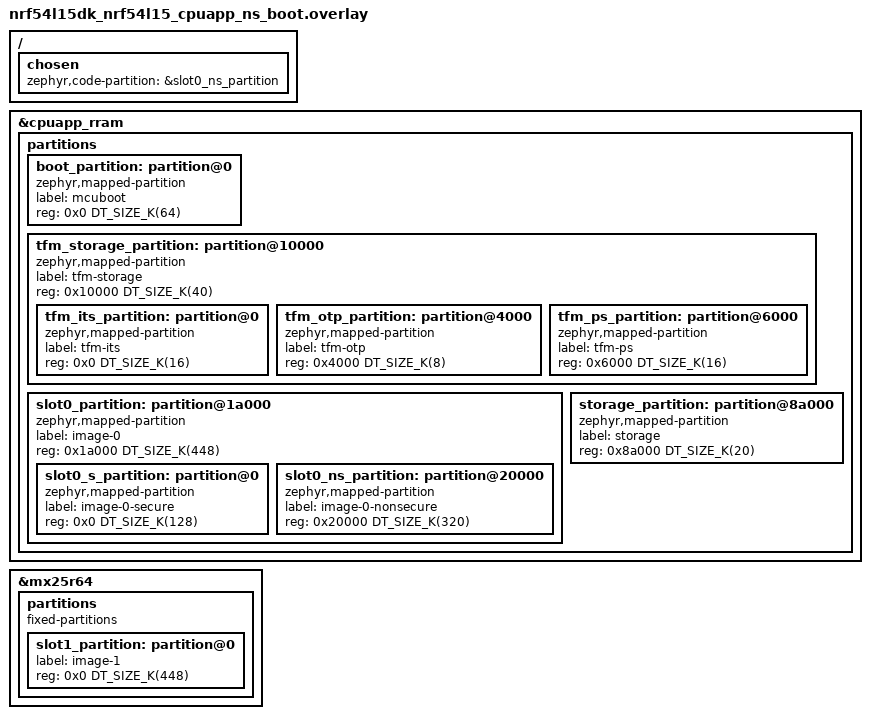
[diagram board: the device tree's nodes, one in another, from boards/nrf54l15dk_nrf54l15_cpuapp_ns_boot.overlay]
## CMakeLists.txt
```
#
# Copyright (c) 2022-2026 Nordic Semiconductor
#
# SPDX-License-Identifier: LicenseRef-Nordic-5-Clause
#
cmake_minimum_required(VERSION 3.20.0)

find_package(Zephyr REQUIRED HINTS $ENV{ZEPHYR_BASE})
project(input_device)

if(CONFIG_PROVISIONER)
  add_subdirectory(provisioner)
else()
  add_subdirectory(src)
  target_include_directories(app PRIVATE include)
endif()
```

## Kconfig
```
#
# Copyright (c) 2024-2026 Nordic Semiconductor
#
# SPDX-License-Identifier: LicenseRef-Nordic-5-Clause
#

source "Kconfig.zephyr"

config SETTINGS
	default y

config ZMS
	default y if (SOC_FLASH_NRF_RRAM || SOC_FLASH_NRF_MRAM)

config NVS
	default y if !(SOC_FLASH_NRF_RRAM || SOC_FLASH_NRF_MRAM)
```

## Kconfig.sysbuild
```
#
# Copyright (c) 2023-2026 Nordic Semiconductor
#
# SPDX-License-Identifier: LicenseRef-Nordic-5-Clause
#

config PARTITION_MANAGER
	default n

menu "Fast Pair credentials"

config BT_FAST_PAIR_MODEL_ID
	default 0x2A410B

# The Anti-Spoofing Private Key is confidential and must be handled securely.
# The following key is only used for demonstration purposes and must not be used in production.
config BT_FAST_PAIR_ANTI_SPOOFING_PRIVATE_KEY
	default "Unoh+nycK/ZJ7k3dHsdcNpiP1SfOy0P/Lx5XixyYois="

endmenu

config NRF_DEFAULT_IPC_RADIO
	default y

source "share/sysbuild/Kconfig"
```

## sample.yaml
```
sample:
  name: Fast Pair input device
  description: Bluetooth Fast Pair Provider sample setup for the input device use
    case
tests:
  sample.bluetooth.fast_pair.input_device:
    build_only: true
    sysbuild: true
    integration_platforms:
      - nrf52dk/nrf52832
      - nrf52840dk/nrf52840
      - nrf5340dk/nrf5340/cpuapp
      - nrf54l15dk/nrf54l05/cpuapp
      - nrf54l15dk/nrf54l15/cpuapp/ns
      - nrf54lm20dk/nrf54lm20a/cpuapp
      - nrf54lm20dk/nrf54lm20b/cpuapp
      - nrf54ls05dk/nrf54ls05b/cpuapp
    platform_allow:
      - nrf52dk/nrf52832
      - nrf52840dk/nrf52840
      - nrf5340dk/nrf5340/cpuapp
      - nrf54l15dk/nrf54l05/cpuapp
      - nrf54l15dk/nrf54l10/cpuapp
      - nrf54l15dk/nrf54l15/cpuapp
      - nrf54l15dk/nrf54l15/cpuapp/ns
      - nrf54lm20dk/nrf54lm20a/cpuapp
      - nrf54lm20dk/nrf54lm20b/cpuapp
      - nrf54ls05dk/nrf54ls05b/cpuapp
    tags:
      - bluetooth
      - ci_build
      - sysbuild
      - ci_samples_bluetooth
  sample.bluetooth.fast_pair.input_device.pm_legacy:
    build_only: true
    sysbuild: true
    integration_platforms:
      - nrf52840dk/nrf52840
      - nrf5340dk/nrf5340/cpuapp
      - nrf5340dk/nrf5340/cpuapp/ns
      - nrf54l15dk/nrf54l15/cpuapp
    platform_allow:
      - nrf52840dk/nrf52840
      - nrf5340dk/nrf5340/cpuapp
      - nrf5340dk/nrf5340/cpuapp/ns
      - nrf54l15dk/nrf54l15/cpuapp
    tags:
      - bluetooth
      - ci_build
      - sysbuild
      - ci_samples_bluetooth
    extra_args:
      - SB_CONFIG_PARTITION_MANAGER=y

  sample.bluetooth.fast_pair.input_device.ns.provisioner:
    build_only: true
    sysbuild: true
    integration_platforms:
      - nrf54l15dk/nrf54l15/cpuapp/ns
    platform_allow:
      - nrf54l15dk/nrf54l15/cpuapp/ns
    tags:
      - bluetooth
      - ci_build
      - sysbuild
      - ci_samples_bluetooth
    extra_args:
      - FILE_SUFFIX=provisioner

  sample.bluetooth.fast_pair.input_device.ns.mcuboot:
    build_only: true
    sysbuild: true
    integration_platforms:
      - nrf54l15dk/nrf54l15/cpuapp/ns
    platform_allow:
      - nrf54l15dk/nrf54l15/cpuapp/ns
    tags:
      - bluetooth
      - ci_build
      - sysbuild
      - ci_samples_bluetooth
    extra_args:
      - FILE_SUFFIX=mcuboot

  sample.bluetooth.fast_pair.input_device.ns.mcuboot_provisioner:
    build_only: true
    sysbuild: true
    integration_platforms:
      - nrf54l15dk/nrf54l15/cpuapp/ns
    platform_allow:
      - nrf54l15dk/nrf54l15/cpuapp/ns
    tags:
      - bluetooth
      - ci_build
      - sysbuild
      - ci_samples_bluetooth
    extra_args:
      - FILE_SUFFIX=mcuboot_provisioner
```

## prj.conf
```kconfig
#
# Copyright (c) 2022-2026 Nordic Semiconductor
#
# SPDX-License-Identifier: LicenseRef-Nordic-5-Clause
#

CONFIG_NCS_SAMPLES_DEFAULTS=y

CONFIG_SYSTEM_WORKQUEUE_PRIORITY=-1
CONFIG_SYSTEM_WORKQUEUE_STACK_SIZE=2048

CONFIG_DK_LIBRARY=y

# Enable settings to store data in non-volatile memory
CONFIG_FLASH=y
CONFIG_FLASH_MAP=y
CONFIG_BT_SETTINGS=y

CONFIG_BT=y
CONFIG_BT_RX_STACK_SIZE=3072
CONFIG_BT_DEVICE_NAME="Nordic_Fast_Pair"
CONFIG_BT_PERIPHERAL=y
CONFIG_BT_PERIPHERAL_PREF_MIN_INT=6
CONFIG_BT_PERIPHERAL_PREF_MAX_INT=6
CONFIG_BT_PERIPHERAL_PREF_LATENCY=99
CONFIG_BT_PERIPHERAL_PREF_TIMEOUT=400
# Appear as a Generic Human Interface Device
CONFIG_BT_DEVICE_APPEARANCE=960

CONFIG_BT_ADV_PROV=y
CONFIG_BT_ADV_PROV_FLAGS=y
CONFIG_BT_ADV_PROV_TX_POWER=y
CONFIG_BT_ADV_PROV_FAST_PAIR=y

CONFIG_BT_ADV_PROV_DEVICE_NAME=y
CONFIG_BT_ADV_PROV_DEVICE_NAME_SD=y
CONFIG_BT_ADV_PROV_GAP_APPEARANCE=y
CONFIG_BT_ADV_PROV_GAP_APPEARANCE_SD=y

# Align the advertised TX power with Fast Pair expectations.
# The value has been tailored for following DKs:
#   * nrf52dk/nrf52832
#   * nrf52833dk/nrf52833
#   * nrf52840dk/nrf52840
#   * nrf5340dk/nrf5340/cpuapp(/ns)
#   * nrf54lm20dk/nrf54lm20a/cpuapp
#   * nrf54lm20dk/nrf54lm20b/cpuapp
CONFIG_BT_ADV_PROV_TX_POWER_CORRECTION_VAL=-15

# Disable automatic initiation of PHY updates.
# Workaround to prevent disconnection with reason 42 (BT_HCI_ERR_DIFF_TRANS_COLLISION).
# Some Android phones reply to the LL_PHY_REQ and at the same time initiate a connection
# update which triggers an invalid procedure collision.
CONFIG_BT_AUTO_PHY_UPDATE=n

CONFIG_BT_ID_MAX=1
CONFIG_BT_MAX_CONN=1
CONFIG_BT_MAX_PAIRED=8

CONFIG_BT_SMP=y
CONFIG_BT_PRIVACY=y
CONFIG_BT_RPA_TIMEOUT=960
CONFIG_BT_FAST_PAIR=y
CONFIG_BT_FAST_PAIR_USE_CASE_INPUT_DEVICE=y
CONFIG_BT_FAST_PAIR_BN=y

CONFIG_LOG=y
CONFIG_BT_FAST_PAIR_LOG_LEVEL_DBG=y

CONFIG_BT_HIDS=y
CONFIG_BT_HIDS_DEFAULT_PERM_RW_ENCRYPT=y
CONFIG_BT_CONN_CTX=y

# Enable BAS to comply with HID over GATT profile
CONFIG_BT_BAS=y

# Fill DIS characteristic to comply with HID over GATT profile
CONFIG_BT_DIS_MANUF_NAME=y
CONFIG_BT_DIS_MANUF_NAME_STR="NordicSemiconductor"
CONFIG_BT_DIS_PNP=y
CONFIG_BT_DIS_PNP_VID_SRC=2
CONFIG_BT_DIS_PNP_VID=0x1915
CONFIG_BT_DIS_PNP_PID=0xEEED

# Enable code partitioning with DTS
CONFIG_USE_DT_CODE_PARTITION=y
```

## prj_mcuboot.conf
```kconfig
#
# Copyright (c) 2026 Nordic Semiconductor ASA
#
# SPDX-License-Identifier: LicenseRef-Nordic-5-Clause
#

CONFIG_NCS_SAMPLES_DEFAULTS=y

CONFIG_SYSTEM_WORKQUEUE_PRIORITY=-1
CONFIG_SYSTEM_WORKQUEUE_STACK_SIZE=2048

CONFIG_DK_LIBRARY=y

# Enable settings to store data in non-volatile memory
CONFIG_FLASH=y
CONFIG_FLASH_MAP=y
CONFIG_BT_SETTINGS=y

CONFIG_BT=y
CONFIG_BT_RX_STACK_SIZE=3072
CONFIG_BT_DEVICE_NAME="Nordic_Fast_Pair"
CONFIG_BT_PERIPHERAL=y
CONFIG_BT_PERIPHERAL_PREF_MIN_INT=6
CONFIG_BT_PERIPHERAL_PREF_MAX_INT=6
CONFIG_BT_PERIPHERAL_PREF_LATENCY=99
CONFIG_BT_PERIPHERAL_PREF_TIMEOUT=400
# Appear as a Generic Human Interface Device
CONFIG_BT_DEVICE_APPEARANCE=960

CONFIG_BT_ADV_PROV=y
CONFIG_BT_ADV_PROV_FLAGS=y
CONFIG_BT_ADV_PROV_TX_POWER=y
CONFIG_BT_ADV_PROV_FAST_PAIR=y

CONFIG_BT_ADV_PROV_DEVICE_NAME=y
CONFIG_BT_ADV_PROV_DEVICE_NAME_SD=y
CONFIG_BT_ADV_PROV_GAP_APPEARANCE=y
CONFIG_BT_ADV_PROV_GAP_APPEARANCE_SD=y

# Align the advertised TX power with Fast Pair expectations.
# The value has been tailored for following DKs:
#   * nrf52dk/nrf52832
#   * nrf52833dk/nrf52833
#   * nrf52840dk/nrf52840
#   * nrf5340dk/nrf5340/cpuapp(/ns)
#   * nrf54lm20dk/nrf54lm20a/cpuapp
#   * nrf54lm20dk/nrf54lm20b/cpuapp
CONFIG_BT_ADV_PROV_TX_POWER_CORRECTION_VAL=-15

# Disable automatic initiation of PHY updates.
# Workaround to prevent disconnection with reason 42 (BT_HCI_ERR_DIFF_TRANS_COLLISION).
# Some Android phones reply to the LL_PHY_REQ and at the same time initiate a connection
# update which triggers an invalid procedure collision.
CONFIG_BT_AUTO_PHY_UPDATE=n

CONFIG_BT_ID_MAX=1
CONFIG_BT_MAX_CONN=1
CONFIG_BT_MAX_PAIRED=8

CONFIG_BT_SMP=y
CONFIG_BT_PRIVACY=y
CONFIG_BT_RPA_TIMEOUT=960
CONFIG_BT_FAST_PAIR=y
CONFIG_BT_FAST_PAIR_USE_CASE_INPUT_DEVICE=y
CONFIG_BT_FAST_PAIR_BN=y

CONFIG_LOG=y
CONFIG_BT_FAST_PAIR_LOG_LEVEL_DBG=y

CONFIG_BT_HIDS=y
CONFIG_BT_HIDS_DEFAULT_PERM_RW_ENCRYPT=y
CONFIG_BT_CONN_CTX=y

# Enable BAS to comply with HID over GATT profile
CONFIG_BT_BAS=y

# Fill DIS characteristic to comply with HID over GATT profile
CONFIG_BT_DIS_MANUF_NAME=y
CONFIG_BT_DIS_MANUF_NAME_STR="NordicSemiconductor"
CONFIG_BT_DIS_PNP=y
CONFIG_BT_DIS_PNP_VID_SRC=2
CONFIG_BT_DIS_PNP_VID=0x1915
CONFIG_BT_DIS_PNP_PID=0xEEED

# Enable code partitioning with DTS
CONFIG_USE_DT_CODE_PARTITION=y

# Enable BLE OTA DFU
CONFIG_NCS_SAMPLE_MCUMGR_BT_OTA_DFU=y
```

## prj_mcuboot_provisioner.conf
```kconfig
#
# Copyright (c) 2026 Nordic Semiconductor ASA
#
# SPDX-License-Identifier: LicenseRef-Nordic-5-Clause
#

CONFIG_SETTINGS=n

CONFIG_LOG=y
CONFIG_NCS_SAMPLES_DEFAULTS=y
CONFIG_LOG_MODE_IMMEDIATE=y
CONFIG_MAIN_STACK_SIZE=4096
```

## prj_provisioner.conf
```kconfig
#
# Copyright (c) 2026 Nordic Semiconductor ASA
#
# SPDX-License-Identifier: LicenseRef-Nordic-5-Clause
#

CONFIG_SETTINGS=n

CONFIG_LOG=y
CONFIG_NCS_SAMPLES_DEFAULTS=y
CONFIG_LOG_MODE_IMMEDIATE=y
CONFIG_MAIN_STACK_SIZE=4096

CONFIG_BT=y
CONFIG_BT_FAST_PAIR=y
CONFIG_BT_FAST_PAIR_CRYPTO_PSA=y
```

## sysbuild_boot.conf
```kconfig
#
# Copyright (c) 2026 Nordic Semiconductor
#
# SPDX-License-Identifier: LicenseRef-Nordic-5-Clause
#

# Sysbuild configuration for the "build_ns_boot" flavor:
#   /ns (TF-M) + MCUboot bootloader with DFU + runtime Fast Pair provisioner.
#
# Selected with:
#   west build -b nrf54l15dk/nrf54l15/cpuapp/ns -d build_ns_boot -- -DFILE_SUFFIX=boot
#
# This file is only read when FILE_SUFFIX=boot, so the plain (no-suffix) standard
# and /ns builds are completely unaffected.

# This sample describes its flash layout with devicetree partitions, not the
# Partition Manager.
SB_CONFIG_PARTITION_MANAGER=n

# MCUboot bootloader.
SB_CONFIG_BOOTLOADER_MCUBOOT=y

# Overwrite-only upgrade mode. The secondary slot lives in the external SPI-NOR
# flash (see the boards/*_ns_boot.overlay), so direct-xip is not possible
# (external flash is not execute-in-place on nRF54L) and the "pure" signature
# type is unsupported with an external secondary slot. In overwrite-only mode
# MCUboot copies the update image from the external secondary slot into the
# internal primary slot before booting it.
SB_CONFIG_MCUBOOT_MODE_OVERWRITE_ONLY=y

# Hardware-accelerated Ed25519 image signature with the public key stored in the
# CRACEN KMU. The key is provisioned into the KMU by the west runner at flash
# time (see the README/provisioning notes), which requires `west flash --erase`
# or `--recover`.
SB_CONFIG_BOOT_SIGNATURE_TYPE_ED25519=y
SB_CONFIG_MCUBOOT_SIGNATURE_USING_KMU=y
SB_CONFIG_BOOT_SIGNATURE_KEY_FILE="\${SB_APPLICATION_CONFIG_DIR}/sysbuild/boot_signature_key_file_ed25519.pem"
SB_CONFIG_MCUBOOT_GENERATE_DEFAULT_KEY_FILE=y
```

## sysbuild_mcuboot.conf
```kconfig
#
# Copyright (c) 2026 Nordic Semiconductor
#
# SPDX-License-Identifier: LicenseRef-Nordic-5-Clause
#

# Sysbuild configuration for the MCUboot /ns (TF-M) flavor.
#
# Selected automatically with FILE_SUFFIX=mcuboot (standard Zephyr sysbuild
# file-suffix mechanism). The application source is chosen with APP_SOURCE:
#   west build -b nrf54l15dk/nrf54l15/cpuapp/ns -d build_mcuboot -- -DFILE_SUFFIX=mcuboot
#   west build -b nrf54l15dk/nrf54l15/cpuapp/ns -d build_mcuboot -- \
#     -DFILE_SUFFIX=mcuboot -DAPP_SOURCE=provisioner
#
# Plain /ns builds without MCUboot omit FILE_SUFFIX=mcuboot.

# This sample describes its flash layout with devicetree partitions.
SB_CONFIG_PARTITION_MANAGER=n

# MCUboot bootloader. The application executes in place from internal RRAM: it
# runs directly from the primary slot, no copy-to-RAM.
#
# Overwrite-only mode keeps this to a single application image that the nRF
# Connect SDK signs automatically - there is no image variant and no manual
# signing step. (Direct-XIP is not used because a TF-M /ns image is split into a
# secure and a non-secure partition; the alternate-slot variant would span both
# slots and exceed a single slot.)
SB_CONFIG_BOOTLOADER_MCUBOOT=y
SB_CONFIG_MCUBOOT_MODE_SWAP_USING_MOVE=y

# Hardware Ed25519 image signature with the public key stored in the CRACEN KMU.
# The key is provisioned by the west runner at flash time, hence `--erase`/`--recover`.
SB_CONFIG_BOOT_SIGNATURE_TYPE_ED25519=y
SB_CONFIG_MCUBOOT_SIGNATURE_USING_KMU=y
SB_CONFIG_BOOT_SIGNATURE_KEY_FILE="\${SB_APPLICATION_CONFIG_DIR}/sysbuild/boot_signature_key_file_ed25519.pem"
SB_CONFIG_MCUBOOT_GENERATE_DEFAULT_KEY_FILE=y
```

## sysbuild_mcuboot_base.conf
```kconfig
#
# Copyright (c) 2026 Nordic Semiconductor
#
# SPDX-License-Identifier: LicenseRef-Nordic-5-Clause
#

# Shared MCUboot sysbuild settings for FILE_SUFFIX=mcuboot and mcuboot_provisioner.
# Merged via SB_EXTRA_CONF_FILE in sysbuild/CMakeLists.txt (.conf fragments do not
# support #include; this is the single source of truth for both variants).
#
# Plain /ns builds without those suffixes omit this file.

# This sample describes its flash layout with devicetree partitions.
SB_CONFIG_PARTITION_MANAGER=n

# MCUboot bootloader. The application executes in place from internal RRAM: it
# runs directly from the primary slot, no copy-to-RAM.
#
# Swap-using-move mode: signed application images in primary/secondary slots.
# (Direct-XIP is not used because a TF-M /ns image is split into a secure and a
# non-secure partition; the alternate-slot variant would span both slots and
# exceed a single slot.)
SB_CONFIG_BOOTLOADER_MCUBOOT=y
SB_CONFIG_MCUBOOT_MODE_SWAP_USING_MOVE=y

# Hardware Ed25519 image signature with the public key stored in the CRACEN KMU.
# The key is provisioned by the west runner at flash time, hence `--erase`/`--recover`.
SB_CONFIG_BOOT_SIGNATURE_TYPE_ED25519=y
SB_CONFIG_MCUBOOT_SIGNATURE_USING_KMU=y
SB_CONFIG_BOOT_SIGNATURE_KEY_FILE="\${SB_APPLICATION_CONFIG_DIR}/sysbuild/boot_signature_key_file_ed25519.pem"
SB_CONFIG_MCUBOOT_GENERATE_DEFAULT_KEY_FILE=y
```

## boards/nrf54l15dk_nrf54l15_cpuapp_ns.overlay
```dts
/*
 * Copyright (c) 2026 Nordic Semiconductor ASA
 *
 * SPDX-License-Identifier: LicenseRef-Nordic-5-Clause
 */

&cpuapp_rram {
	/delete-node/ partitions;

	partitions {
		ranges;
		#address-cells = <1>;
		#size-cells = <1>;

		/*
		 * This is an example of partitioning flash for a non-MCUboot project
		 * with TF-M enabled. Everything up to and including tfm_storage is
		 * Secure; slot0_ns and everything above the boundary is Non-Secure.
		 */

		slot0_s_partition: partition@0 {
			compatible = "zephyr,mapped-partition";
			label = "image-0";
			reg = <0x0 DT_SIZE_K(512)>;
		};

		tfm_storage_partition: partition@80000 {
			compatible = "zephyr,mapped-partition";
			label = "tfm-storage";
			reg = <0x80000 DT_SIZE_K(40)>;
			ranges = <0x0 0x80000 DT_SIZE_K(40)>;
			#address-cells = <1>;
			#size-cells = <1>;

			tfm_its_partition: partition@0 {
				compatible = "zephyr,mapped-partition";
				label = "tfm-its";
				reg = <0x0 DT_SIZE_K(16)>;
			};

			tfm_otp_partition: partition@4000 {
				compatible = "zephyr,mapped-partition";
				label = "tfm-otp";
				reg = <0x4000 DT_SIZE_K(8)>;
			};

			tfm_ps_partition: partition@6000 {
				compatible = "zephyr,mapped-partition";
				label = "tfm-ps";
				reg = <0x6000 DT_SIZE_K(16)>;
			};
		};

		/*
		 * slot0_ns_partition's base address is the Secure/Non-Secure boundary
		 * (non_secure_partition_base). It must be aligned to the TrustZone flash
		 * region size (CONFIG_NRF_TRUSTZONE_FLASH_REGION_SIZE; 4 KB MPC granularity).
		 * The non-secure application begins AT this boundary. Everything at or above
		 * it is attributed Non-Secure, so no Secure content — TF-M's ITS/PS/OTP or
		 * secure code — may be placed there.
		 */

		slot0_ns_partition: partition@8a000 {
			compatible = "zephyr,mapped-partition";
			label = "image-0-nonsecure";
			reg = <0x8a000 DT_SIZE_K(944)>;
		};

		storage_partition: partition@178000 {
			compatible = "zephyr,mapped-partition";
			label = "storage";
			reg = <0x178000 DT_SIZE_K(20)>;
		};
	};
};
```

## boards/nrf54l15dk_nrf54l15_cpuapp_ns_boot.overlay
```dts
/*
 * Copyright (c) 2026 Nordic Semiconductor ASA
 *
 * SPDX-License-Identifier: LicenseRef-Nordic-5-Clause
 */

/*
 * Flash layout for the MCUboot-enabled /ns (TF-M) build ("build_ns_boot").
 *
 * Slot sizes are derived from the actual footprint of the standard TF-M /ns
 * build (secure image ~85 KB, non-secure application ~222 KB) with headroom for
 * DFU growth and debug builds, rounded to keep the Secure/Non-Secure boundary
 * aligned to the 4 KB TrustZone flash region granularity:
 *
 *   boot_partition ............ 64 KB   MCUboot (secure, immutable)
 *   tfm_storage_partition ..... 40 KB   secure (ITS 16 / OTP 8 / PS 16)
 *   slot0_partition .......... 448 KB   MCUboot primary image (image-0), of which
 *       slot0_s_partition .... 128 KB       secure image (tfm_s + NSC veneers)
 *       --- Secure / Non-Secure boundary @ 0x3a000 (232 KB) ---
 *       slot0_ns_partition ... 320 KB       non-secure application
 *   storage_partition ......... 20 KB   non-secure settings storage
 *
 * The MCUboot secondary slot (image-1, same 448 KB) is placed in the external
 * SPI-NOR flash (see &mx25r64 below), so only ONE copy of the ~448 KB image
 * occupies internal RRAM. This is what makes MCUboot + TF-M fit on the nRF54L15
 * (two internal slots would not).
 */

/ {
	chosen {
		zephyr,code-partition = &slot0_ns_partition;
	};
};

&cpuapp_rram {
	/delete-node/ partitions;

	partitions {
		ranges;
		#address-cells = <1>;
		#size-cells = <1>;

		boot_partition: partition@0 {
			compatible = "zephyr,mapped-partition";
			label = "mcuboot";
			reg = <0x0 DT_SIZE_K(64)>;
		};

		tfm_storage_partition: partition@10000 {
			compatible = "zephyr,mapped-partition";
			label = "tfm-storage";
			reg = <0x10000 DT_SIZE_K(40)>;
			ranges = <0x0 0x10000 DT_SIZE_K(40)>;
			#address-cells = <1>;
			#size-cells = <1>;

			tfm_its_partition: partition@0 {
				compatible = "zephyr,mapped-partition";
				label = "tfm-its";
				reg = <0x0 DT_SIZE_K(16)>;
			};

			tfm_otp_partition: partition@4000 {
				compatible = "zephyr,mapped-partition";
				label = "tfm-otp";
				reg = <0x4000 DT_SIZE_K(8)>;
			};

			tfm_ps_partition: partition@6000 {
				compatible = "zephyr,mapped-partition";
				label = "tfm-ps";
				reg = <0x6000 DT_SIZE_K(16)>;
			};
		};

		slot0_partition: partition@1a000 {
			compatible = "zephyr,mapped-partition";
			label = "image-0";
			reg = <0x1a000 DT_SIZE_K(448)>;
			ranges = <0x0 0x1a000 DT_SIZE_K(448)>;
			#address-cells = <1>;
			#size-cells = <1>;

			slot0_s_partition: partition@0 {
				compatible = "zephyr,mapped-partition";
				label = "image-0-secure";
				reg = <0x0 DT_SIZE_K(128)>;
			};

			/*
			 * slot0_ns_partition's base address is the Secure/Non-Secure boundary
			 * (non_secure_partition_base). It must be aligned to the TrustZone flash
			 * region size (CONFIG_NRF_TRUSTZONE_FLASH_REGION_SIZE; 4 KB MPC granularity).
			 * Everything at or above it is attributed Non-Secure.
			 */
			slot0_ns_partition: partition@20000 {
				compatible = "zephyr,mapped-partition";
				label = "image-0-nonsecure";
				reg = <0x20000 DT_SIZE_K(320)>;
			};
		};

		storage_partition: partition@8a000 {
			compatible = "zephyr,mapped-partition";
			label = "storage";
			reg = <0x8a000 DT_SIZE_K(20)>;
		};
	};
};

/*
 * MCUboot secondary slot (image-1) in the external SPI-NOR flash (MX25R6435F on
 * &spi00). Its size equals the primary slot (slot0 = 448 KB) and is aligned to
 * the 4 KB sector erase size of the external flash. Requires the SPI NOR driver
 * (CONFIG_SPI, CONFIG_SPI_NOR) in both the application and the MCUboot images.
 */
&mx25r64 {
	status = "okay";

	partitions {
		compatible = "fixed-partitions";
		#address-cells = <1>;
		#size-cells = <1>;

		slot1_partition: partition@0 {
			label = "image-1";
			reg = <0x0 DT_SIZE_K(448)>;
		};
	};
};
```

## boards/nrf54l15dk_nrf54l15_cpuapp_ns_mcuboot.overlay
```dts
/*
 * Copyright (c) 2026 Nordic Semiconductor ASA
 *
 * SPDX-License-Identifier: LicenseRef-Nordic-5-Clause
 */

/*
 * Flash layout for the MCUboot-enabled /ns (TF-M) build.
 *
 * Slot sizes are derived from the standard TF-M /ns build footprint with
 * headroom for DFU growth and debug builds, aligned to the 4 KB TrustZone
 * flash region granularity.
 */

/ {
	chosen {
		zephyr,code-partition = &slot0_ns_partition;
	};
};

&cpuapp_rram {
	/delete-node/ partitions;

	partitions {
		ranges;
		#address-cells = <1>;
		#size-cells = <1>;

		boot_partition: partition@0 {
			compatible = "zephyr,mapped-partition";
			label = "mcuboot";
			reg = <0x0 DT_SIZE_K(64)>;
		};

		tfm_storage_partition: partition@10000 {
			compatible = "zephyr,mapped-partition";
			label = "tfm-storage";
			reg = <0x10000 DT_SIZE_K(40)>;
			ranges = <0x0 0x10000 DT_SIZE_K(40)>;
			#address-cells = <1>;
			#size-cells = <1>;

			tfm_its_partition: partition@0 {
				compatible = "zephyr,mapped-partition";
				label = "tfm-its";
				reg = <0x0 DT_SIZE_K(16)>;
			};

			tfm_otp_partition: partition@4000 {
				compatible = "zephyr,mapped-partition";
				label = "tfm-otp";
				reg = <0x4000 DT_SIZE_K(8)>;
			};

			tfm_ps_partition: partition@6000 {
				compatible = "zephyr,mapped-partition";
				label = "tfm-ps";
				reg = <0x6000 DT_SIZE_K(16)>;
			};
		};

		slot0_partition: partition@1a000 {
			compatible = "zephyr,mapped-partition";
			label = "image-0";
			reg = <0x1a000 DT_SIZE_K(512)>;
			ranges = <0x0 0x1a000 DT_SIZE_K(512)>;
			#address-cells = <1>;
			#size-cells = <1>;

			slot0_s_partition: partition@0 {
				compatible = "zephyr,mapped-partition";
				label = "image-0-secure";
				reg = <0x0 DT_SIZE_K(128)>;
			};

			slot0_ns_partition: partition@20000 {
				compatible = "zephyr,mapped-partition";
				label = "image-0-nonsecure";
				reg = <0x20000 DT_SIZE_K(384)>;
			};
		};

		slot1_partition: partition@9a000 {
			compatible = "zephyr,mapped-partition";
			label = "image-1";
			reg = <0x9a000 DT_SIZE_K(512)>;
		};

		storage_partition: partition@11a000 {
			compatible = "zephyr,mapped-partition";
			label = "storage";
			reg = <0x11a000 DT_SIZE_K(20)>;
		};
	};
};
```

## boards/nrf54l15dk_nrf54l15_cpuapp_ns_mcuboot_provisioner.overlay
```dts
/*
 * Copyright (c) 2026 Nordic Semiconductor ASA
 *
 * SPDX-License-Identifier: LicenseRef-Nordic-5-Clause
 */

/* Use the target device overlay */
#include "nrf54l15dk_nrf54l15_cpuapp_ns_mcuboot.overlay"
```

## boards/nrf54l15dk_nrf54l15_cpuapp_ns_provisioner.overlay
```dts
/*
 * Copyright (c) 2026 Nordic Semiconductor ASA
 *
 * SPDX-License-Identifier: LicenseRef-Nordic-5-Clause
 */

/* Use the target device overlay */
#include "nrf54l15dk_nrf54l15_cpuapp_ns.overlay"
```

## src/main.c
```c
/*
 * Copyright (c) 2022-2026 Nordic Semiconductor ASA
 *
 * SPDX-License-Identifier: LicenseRef-Nordic-5-Clause
 */

#include <zephyr/kernel.h>
#include <zephyr/sys/__assert.h>
#include <zephyr/bluetooth/bluetooth.h>
#include <zephyr/bluetooth/conn.h>
#include <zephyr/bluetooth/hci.h>
#include <zephyr/settings/settings.h>
#include <bluetooth/fast_pair/fast_pair.h>
#include <bluetooth/adv_prov/fast_pair.h>

#include <dk_buttons_and_leds.h>

#include <zephyr/logging/log.h>
LOG_MODULE_REGISTER(fp_sample, LOG_LEVEL_INF);

#include "bt_adv_helper.h"
#include "hids_helper.h"
#include "battery_module.h"

#include "example_secure_partition_client.h"
#include <psa/protected_storage.h>
#include <psa/crypto.h>


#define RUN_STATUS_LED						DK_LED1
#define CON_STATUS_LED						DK_LED2
#define FP_ADV_MODE_STATUS_LED					DK_LED3

#define FP_ADV_MODE_BUTTON_MASK					DK_BTN1_MSK
#define VOLUME_UP_BUTTON_MASK					DK_BTN2_MSK
#define BOND_REMOVE_BUTTON_MASK					DK_BTN3_MSK
#define VOLUME_DOWN_BUTTON_MASK					DK_BTN4_MSK

#define RUN_LED_BLINK_INTERVAL_MS				1000
#define FP_ADV_MODE_SHOW_UI_INDICATION_LED_BLINK_INTERVAL_MS	500
#define FP_ADV_MODE_HIDE_UI_INDICATION_LED_BLINK_INTERVAL_MS	1500

#define FP_DISC_ADV_TIMEOUT_MINUTES				(10)

#define INIT_SEM_TIMEOUT_SECONDS				(60)

static enum bt_fast_pair_adv_mode fp_adv_mode = BT_FAST_PAIR_ADV_MODE_DISC;
static bool show_ui_pairing = true;
static bool new_adv_session = true;
static struct bt_conn *peer;

static struct k_work bt_adv_restart;
static struct k_work_delayable fp_adv_mode_status_led_handle;
static struct k_work_delayable fp_disc_adv_timeout;

static void init_work_handle(struct k_work *w);

static K_SEM_DEFINE(init_work_sem, 0, 1);
static K_WORK_DEFINE(init_work, init_work_handle);


static void bond_cnt_cb(const struct bt_bond_info *info, void *user_data)
{
	size_t *cnt = user_data;

	(*cnt)++;
}

static size_t bond_cnt(void)
{
	size_t cnt = 0;

	bt_foreach_bond(BT_ID_DEFAULT, bond_cnt_cb, &cnt);

	return cnt;
}

static bool can_pair(void)
{
	return (bond_cnt() < CONFIG_BT_MAX_PAIRED);
}

static void advertising_stop(void)
{
	int ret = k_work_cancel_delayable(&fp_disc_adv_timeout);

	__ASSERT_NO_MSG((ret & ~(K_WORK_CANCELING)) == 0);

	ret = bt_adv_helper_adv_stop();
	if (ret) {
		LOG_ERR("Failed to stop advertising (err %d)", ret);
	}
}

static void advertising_start(void)
{
	int err;
	int ret;

	ARG_UNUSED(ret);

	if (!can_pair()) {
		if ((fp_adv_mode == BT_FAST_PAIR_ADV_MODE_DISC) || show_ui_pairing) {
			LOG_INF("Automatically switching to not discoverable advertising, hide UI "
				"indication, because all bond slots are taken");
			fp_adv_mode = BT_FAST_PAIR_ADV_MODE_NOT_DISC;
			show_ui_pairing = false;

			ret = k_work_reschedule(&fp_adv_mode_status_led_handle, K_NO_WAIT);
			__ASSERT_NO_MSG((ret == 0) || (ret == 1));
		}
	}

	bt_le_adv_prov_fast_pair_show_ui_pairing(show_ui_pairing);

	err = bt_adv_helper_adv_start((fp_adv_mode == BT_FAST_PAIR_ADV_MODE_DISC), new_adv_session);

	new_adv_session = false;

	ret = k_work_cancel_delayable(&fp_disc_adv_timeout);

	/* The advertising_start function may be called from discoverable advertising timeout work
	 * handler. In that case work would initially be in a running state.
	 */
	__ASSERT_NO_MSG((ret & ~(K_WORK_RUNNING | K_WORK_CANCELING)) == 0);

	if ((fp_adv_mode == BT_FAST_PAIR_ADV_MODE_DISC) && !err) {
		ret = k_work_reschedule(&fp_disc_adv_timeout,
					K_MINUTES(FP_DISC_ADV_TIMEOUT_MINUTES));

		__ASSERT_NO_MSG(ret == 1);
	}

	if (!err) {
		if (fp_adv_mode == BT_FAST_PAIR_ADV_MODE_DISC) {
			LOG_INF("Discoverable advertising started");
		} else {
			LOG_INF("Not discoverable advertising started, %s UI indication enabled",
				show_ui_pairing ? "show" : "hide");
		}
	} else {
		LOG_ERR("Advertising failed to start (err %d)", err);
	}
}

static void bt_adv_restart_fn(struct k_work *w)
{
	advertising_start();
}

static void fp_adv_mode_status_led_handle_fn(struct k_work *w)
{
	ARG_UNUSED(w);

	static bool led_on = true;
	int ret;

	ARG_UNUSED(ret);

	switch (fp_adv_mode) {
	case BT_FAST_PAIR_ADV_MODE_DISC:
		dk_set_led_on(FP_ADV_MODE_STATUS_LED);
		break;

	case BT_FAST_PAIR_ADV_MODE_NOT_DISC:
		dk_set_led(FP_ADV_MODE_STATUS_LED, led_on);
		led_on = !led_on;
		ret = k_work_reschedule(&fp_adv_mode_status_led_handle, show_ui_pairing ?
				K_MSEC(FP_ADV_MODE_SHOW_UI_INDICATION_LED_BLINK_INTERVAL_MS) :
				K_MSEC(FP_ADV_MODE_HIDE_UI_INDICATION_LED_BLINK_INTERVAL_MS));
		__ASSERT_NO_MSG(ret == 1);
		break;

	default:
		__ASSERT_NO_MSG(false);
	}
}

static void fp_disc_adv_timeout_fn(struct k_work *w)
{
	ARG_UNUSED(w);

	__ASSERT_NO_MSG(fp_adv_mode == BT_FAST_PAIR_ADV_MODE_DISC);
	__ASSERT_NO_MSG(!peer);

	LOG_INF("Discoverable advertising timed out");

	/* Switch to not discoverable advertising showing UI indication. */
	fp_adv_mode = BT_FAST_PAIR_ADV_MODE_NOT_DISC;
	show_ui_pairing = true;

	fp_adv_mode_status_led_handle_fn(NULL);
	advertising_start();
}

static void connected(struct bt_conn *conn, uint8_t err)
{
	int ret = k_work_cancel_delayable(&fp_disc_adv_timeout);

	__ASSERT_NO_MSG(ret == 0);
	ret = k_work_cancel(&bt_adv_restart);
	__ASSERT_NO_MSG(ret == 0);
	ARG_UNUSED(ret);

	/* Multiple simultaneous connections are not supported by the sample. */
	__ASSERT_NO_MSG(!peer);

	if (err) {
		LOG_WRN("Connection failed, err 0x%02x %s", err, bt_hci_err_to_str(err));
		ret = k_work_submit(&bt_adv_restart);
		__ASSERT_NO_MSG(ret == 1);
		return;
	}

	LOG_INF("Connected");

	dk_set_led_on(CON_STATUS_LED);
	peer = conn;
}

static void disconnected(struct bt_conn *conn, uint8_t reason)
{
	LOG_INF("Disconnected, reason 0x%02x %s", reason, bt_hci_err_to_str(reason));

	dk_set_led_off(CON_STATUS_LED);
	peer = NULL;

	int ret = k_work_submit(&bt_adv_restart);

	__ASSERT_NO_MSG(ret == 1);
	ARG_UNUSED(ret);

	new_adv_session = true;
}

static void security_changed(struct bt_conn *conn, bt_security_t level, enum bt_security_err err)
{
	char addr[BT_ADDR_LE_STR_LEN];

	bt_addr_le_to_str(bt_conn_get_dst(conn), addr, sizeof(addr));

	if (!err) {
		LOG_INF("Security changed: %s level %u", addr, level);
	} else {
		LOG_WRN("Security failed: %s level %u err %d %s", addr, level, err,
			bt_security_err_to_str(err));
	}
}

BT_CONN_CB_DEFINE(conn_callbacks) = {
	.connected        = connected,
	.disconnected     = disconnected,
	.security_changed = security_changed,
};

static void pairing_complete(struct bt_conn *conn, bool bonded)
{
	if (bonded && (fp_adv_mode == BT_FAST_PAIR_ADV_MODE_DISC)) {
		fp_adv_mode = BT_FAST_PAIR_ADV_MODE_NOT_DISC;
		show_ui_pairing = true;
		int ret = k_work_reschedule(&fp_adv_mode_status_led_handle, K_NO_WAIT);

		__ASSERT_NO_MSG((ret == 0) || (ret == 1));
		ARG_UNUSED(ret);
	}
}

static enum bt_security_err pairing_accept(struct bt_conn *conn,
					   const struct bt_conn_pairing_feat *const feat)
{
	ARG_UNUSED(conn);
	ARG_UNUSED(feat);

	enum bt_security_err ret;

	if (fp_adv_mode != BT_FAST_PAIR_ADV_MODE_DISC) {
		LOG_WRN("Normal Bluetooth pairing not allowed outside of pairing mode");
		ret = BT_SECURITY_ERR_PAIR_NOT_ALLOWED;
	} else {
		LOG_INF("Accept normal Bluetooth pairing");
		ret = BT_SECURITY_ERR_SUCCESS;
	}

	return ret;
}

static const char *volume_change_to_str(enum hids_helper_volume_change volume_change)
{
	const char *res = NULL;

	switch (volume_change) {
	case HIDS_HELPER_VOLUME_CHANGE_DOWN:
		res = "Decrease";
		break;

	case HIDS_HELPER_VOLUME_CHANGE_NONE:
		break;

	case HIDS_HELPER_VOLUME_CHANGE_UP:
		res = "Increase";
		break;

	default:
		/* Should not happen. */
		__ASSERT_NO_MSG(false);
		break;
	}

	return res;
}

static void hid_volume_control_send(enum hids_helper_volume_change volume_change)
{
	const char *operation_str = volume_change_to_str(volume_change);
	int err = hids_helper_volume_ctrl(volume_change);

	if (!err) {
		if (operation_str) {
			LOG_INF("%s audio volume", operation_str);
		}
	} else {
		/* HID host not connected or not subscribed. Silently drop HID data. */
	}
}

static void volume_control_btn_handle(uint32_t button_state, uint32_t has_changed)
{
	static enum hids_helper_volume_change volume_change = HIDS_HELPER_VOLUME_CHANGE_NONE;
	enum hids_helper_volume_change new_volume_change = volume_change;

	if (has_changed & VOLUME_UP_BUTTON_MASK) {
		if (button_state & VOLUME_UP_BUTTON_MASK) {
			new_volume_change = HIDS_HELPER_VOLUME_CHANGE_UP;
		} else if (volume_change == HIDS_HELPER_VOLUME_CHANGE_UP) {
			new_volume_change = HIDS_HELPER_VOLUME_CHANGE_NONE;
		}
	}

	if (has_changed & VOLUME_DOWN_BUTTON_MASK) {
		if (button_state & VOLUME_DOWN_BUTTON_MASK) {
			new_volume_change = HIDS_HELPER_VOLUME_CHANGE_DOWN;
		} else if (volume_change == HIDS_HELPER_VOLUME_CHANGE_DOWN) {
			new_volume_change = HIDS_HELPER_VOLUME_CHANGE_NONE;
		}
	}

	if (volume_change != new_volume_change) {
		volume_change = new_volume_change;
		hid_volume_control_send(volume_change);
	}
}

static void fp_adv_mode_btn_handle(uint32_t button_state, uint32_t has_changed)
{
	uint32_t button_pressed = button_state & has_changed;

	if (button_pressed & FP_ADV_MODE_BUTTON_MASK) {
		if (fp_adv_mode == BT_FAST_PAIR_ADV_MODE_DISC) {
			fp_adv_mode = BT_FAST_PAIR_ADV_MODE_NOT_DISC;
			show_ui_pairing = true;
		} else {
			if (show_ui_pairing) {
				show_ui_pairing = false;
			} else {
				fp_adv_mode = BT_FAST_PAIR_ADV_MODE_DISC;
			}
		}

		if (!peer) {
			new_adv_session = true;
			advertising_start();
		}

		int ret = k_work_reschedule(&fp_adv_mode_status_led_handle, K_NO_WAIT);

		__ASSERT_NO_MSG((ret == 0) || (ret == 1));
		ARG_UNUSED(ret);
	}
}

static void bond_remove_btn_handle(uint32_t button_state, uint32_t has_changed)
{
	uint32_t button_pressed = button_state & has_changed;

	if (button_pressed & BOND_REMOVE_BUTTON_MASK) {
		advertising_stop();

		int err = bt_unpair(BT_ID_DEFAULT, NULL);

		if (err) {
			LOG_ERR("Cannot remove bonds (err %d)", err);
		} else {
			LOG_INF("Bonds removed");
		}

		if (!peer) {
			new_adv_session = true;
			advertising_start();
		}
	}
}

static void button_changed(uint32_t button_state, uint32_t has_changed)
{
	__ASSERT_NO_MSG(!k_is_in_isr());
	__ASSERT_NO_MSG(!k_is_preempt_thread());

	fp_adv_mode_btn_handle(button_state, has_changed);
	volume_control_btn_handle(button_state, has_changed);
	bond_remove_btn_handle(button_state, has_changed);
}

static void fp_account_key_written(struct bt_conn *conn)
{
	LOG_INF("Fast Pair Account Key has been written");
}

static void init_work_handle(struct k_work *w)
{
	int err;
	static const struct bt_conn_auth_cb conn_auth_callbacks = {
		.pairing_accept = pairing_accept,
	};
	static struct bt_conn_auth_info_cb auth_info_cb = {
		.pairing_complete = pairing_complete
	};
	static struct bt_fast_pair_info_cb fp_info_callbacks = {
		.account_key_written = fp_account_key_written,
	};

	/* It is assumed that this function executes in the cooperative thread context. */
	__ASSERT_NO_MSG(!k_is_preempt_thread());
	__ASSERT_NO_MSG(!k_is_in_isr());

	err = bt_conn_auth_cb_register(&conn_auth_callbacks);
	if (err) {
		LOG_ERR("Registering authentication callbacks failed (err %d)", err);
		return;
	}

	err = bt_conn_auth_info_cb_register(&auth_info_cb);
	if (err) {
		LOG_ERR("Registering authentication info callbacks failed (err %d)", err);
		return;
	}

	err = bt_fast_pair_info_cb_register(&fp_info_callbacks);
	if (err) {
		LOG_ERR("Registering Fast Pair info callbacks failed (err %d)", err);
		return;
	}

	err = hids_helper_init();
	if (err) {
		LOG_ERR("HIDS init failed (err %d)", err);
		return;
	}

	err = bt_enable(NULL);
	if (err) {
		LOG_ERR("Bluetooth init failed (err %d)", err);
		return;
	}

	LOG_INF("Bluetooth initialized");

	err = settings_load();
	if (err) {
		LOG_ERR("Settings load failed (err: %d)", err);
		return;
	}

	LOG_INF("Settings loaded");

	err = bt_fast_pair_enable();
	if (err) {
		LOG_ERR("Fast Pair enable failed (err: %d)", err);
		return;
	}

	err = dk_leds_init();
	if (err) {
		LOG_ERR("LEDs init failed (err %d)", err);
		return;
	}

	err = battery_module_init();
	if (err) {
		LOG_ERR("Battery module init failed (err %d)", err);
		return;
	}

	err = bt_le_adv_prov_fast_pair_set_battery_mode(BT_FAST_PAIR_ADV_BATTERY_MODE_SHOW_UI_IND);
	if (err) {
		LOG_ERR("Setting advertising battery mode failed (err %d)", err);
		return;
	}

	k_work_init(&bt_adv_restart, bt_adv_restart_fn);
	k_work_init_delayable(&fp_adv_mode_status_led_handle, fp_adv_mode_status_led_handle_fn);
	k_work_init_delayable(&fp_disc_adv_timeout, fp_disc_adv_timeout_fn);

	int ret = k_work_schedule(&fp_adv_mode_status_led_handle, K_NO_WAIT);

	__ASSERT_NO_MSG(ret == 1);
	ret = k_work_submit(&bt_adv_restart);
	__ASSERT_NO_MSG(ret == 1);
	ARG_UNUSED(ret);

	err = dk_buttons_init(button_changed);
	if (err) {
		LOG_ERR("Buttons init failed (err %d)", err);
		return;
	}

	k_sem_give(&init_work_sem);
}

int main(void)
{
	bool run_led_on = true;
	int err;

	LOG_INF("Starting Bluetooth Fast Pair input device sample");

	/* Switch to the cooperative thread context before interaction
	 * with the Fast Pair API.
	 */
	(void) k_work_submit(&init_work);
	err = k_sem_take(&init_work_sem, K_SECONDS(INIT_SEM_TIMEOUT_SECONDS));
	if (err) {
		k_panic();
		return 0;
	}

	LOG_INF("Sample has started");

	uint64_t n;
	for (;;) {
		dk_set_led(RUN_STATUS_LED, run_led_on);
		run_led_on = !run_led_on;

		psa_status_t st = psa_example_secure_partition_get(&n);
		if (st == PSA_SUCCESS) {
			LOG_INF("Fibonacci: %llu", (unsigned long long)n);
		}

		// uint64_t leak;
		// size_t len;
		// st = psa_ps_get(0x2500ULL, 0, sizeof(leak), &leak, &len);
		// LOG_INF("NS direct PS read: %d [leaked val: %llu] (expect DOES_NOT_EXIST or NOT_PERMITTED)", st, leak);

		k_sleep(K_MSEC(RUN_LED_BLINK_INTERVAL_MS));
	}
}
```

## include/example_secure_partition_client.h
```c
#ifndef EXAMPLE_SECURE_PARTITION_CLIENT_H
#define EXAMPLE_SECURE_PARTITION_CLIENT_H

#include <stdint.h>
#include "psa/client.h"
#include "psa_manifest/sid.h"
#include "tfm_ns_interface.h"

psa_status_t psa_example_secure_partition_get(uint64_t *value);

#endif /* EXAMPLE_SECURE_PARTITION_CLIENT_H */
```

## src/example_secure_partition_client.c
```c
#include <stdint.h>
#include "psa/client.h"
#include "psa_manifest/sid.h"
#include "tfm_ns_interface.h"
#include "example_secure_partition_client.h"

psa_status_t psa_example_secure_partition_get(uint64_t *value)
{
    psa_handle_t handle;
    psa_status_t status;
    psa_outvec out = { .base = value, .len = sizeof(*value) };

    if (!value) {
        return PSA_ERROR_INVALID_ARGUMENT;
    }

    handle = psa_connect(TFM_EXAMPLE_GET_SID, TFM_EXAMPLE_GET_VERSION);
    if (!PSA_HANDLE_IS_VALID(handle)) {
        return PSA_ERROR_GENERIC_ERROR;
    }
    
    status = psa_call(handle, PSA_IPC_CALL, NULL, 0, &out, 1);
    psa_close(handle);
    return status;
}
```
